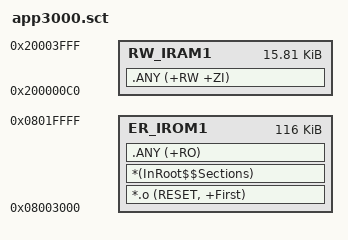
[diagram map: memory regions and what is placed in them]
; *************************************************************
; *** Scatter-Loading Description File generated by uVision ***
; *** Modified by Michael Tien, Nov 30, 2016
; *************************************************************
; 
; For direct debugging, use the following two lines  
;LR_IROM1 0x08000000 0x00020000  {    ; load region size_region for debugging
;   ER_IROM1 0x08000000 0x00020000  {  ; load address = execution address
; For bootload application, use the following two lines
LR_IROM1 0x08003000 0x0001D000  {    ; load region size_region
  ER_IROM1 0x08003000 0x0001D000  {  ; load address = execution address
   *.o (RESET, +First)
   *(InRoot$$Sections)
   .ANY (+RO)
  }
  RW_IRAM1 0x200000C0 0x00003F40  {  ; RW data
   .ANY (+RW +ZI)
  }
}

